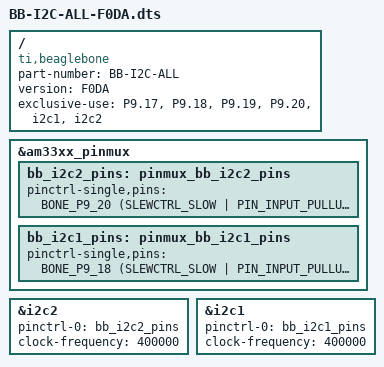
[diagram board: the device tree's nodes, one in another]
/*
 * Copyright (C) 2015 Robert Nelson <robertcnelson@gmail.com>
 *
 * This program is free software; you can redistribute it and/or modify
 * it under the terms of the GNU General Public License version 2 as
 * published by the Free Software Foundation.
 */
/dts-v1/;
/plugin/;

#include <dt-bindings/board/am335x-bbw-bbb-base.h>
#include <dt-bindings/gpio/gpio.h>
#include <dt-bindings/pinctrl/am33xx.h>

/ {
	compatible = "ti,beaglebone", "ti,beaglebone-black", "ti,beaglebone-green";

	/* identification */
	part-number = "BB-I2C-ALL";
	version = "F0DA";

	/* state the resources this cape uses */
	exclusive-use =
		/* the pin header uses */
		"P9.17",	/* i2c1_scl */
		"P9.18",	/* i2c1_sda */
		"P9.19",	/* i2c2_scl */
		"P9.20",	/* i2c2_sda */
		"i2c1",
		"i2c2";


	fragment@0 {
		target = <&am33xx_pinmux>;
		__overlay__ {
			bb_i2c2_pins: pinmux_bb_i2c2_pins {
				pinctrl-single,pins = <
					BONE_P9_20 (SLEWCTRL_SLOW | PIN_INPUT_PULLUP | MUX_MODE3) /* spi0_d1.i2c2_sda */
					BONE_P9_19 (SLEWCTRL_SLOW | PIN_INPUT_PULLUP | MUX_MODE3) /* spi0_cs0.i2c2_scl */
				>;
			};
		};
	};

        fragment@1 {
                target = <&am33xx_pinmux>;
                __overlay__ {
                        bb_i2c1_pins: pinmux_bb_i2c1_pins {
                                pinctrl-single,pins = <
                                        BONE_P9_18 (SLEWCTRL_SLOW | PIN_INPUT_PULLUP | MUX_MODE2) /* spi0_d1.i2c1_sda */
                                        BONE_P9_17 (SLEWCTRL_SLOW | PIN_INPUT_PULLUP | MUX_MODE2) /* spi0_cs0.i2c1_scl */
                                >;
                        };

		};
        };


	fragment@2 {
		target = <&i2c2>;
		__overlay__ {
			status = "okay";
			pinctrl-names = "default";
			pinctrl-0 = <&bb_i2c2_pins>;

			clock-frequency = <400000>;

			#address-cells = <1>;
			#size-cells = <0>;
		};
	};

	fragment@3 {
		target = <&i2c1>;
		__overlay__ {
			status = "okay";
			pinctrl-names = "default";
			pinctrl-0 = <&bb_i2c1_pins>;

			clock-frequency = <400000>;

			#address-cells = <1>;
			#size-cells = <0>;

		};
	};
};
